# NUC121AE_v1 register map
File version: 1.0
Registers are 32-bit, read-write, reset 0x0 unless marked. A register's access mark holds for its fields unless they carry their own. Offsets are from the block's base; [hi:lo] are bit positions; {n}, {i} and the like mark numbered series.

## SCS — SYST_NVIC_SCS Register Map
Base 0xE000E000
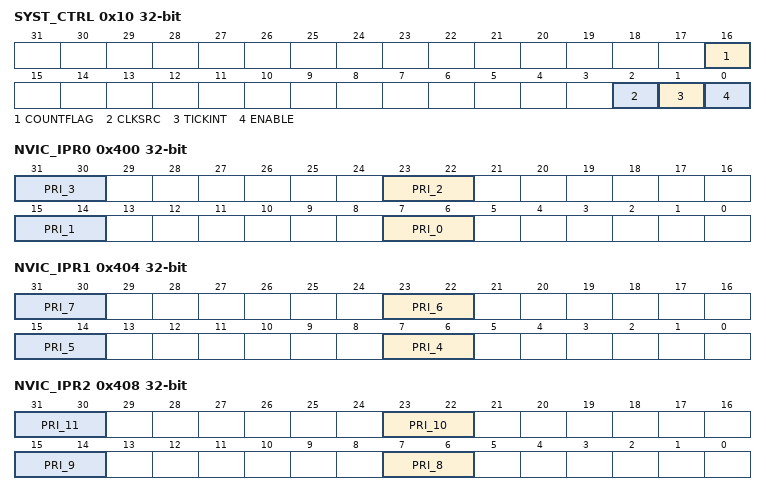
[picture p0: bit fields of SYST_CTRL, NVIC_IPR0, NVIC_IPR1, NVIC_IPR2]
0x10 SYST_CTRL — SysTick Control and Status Register
  [16] COUNTFLAG — System Tick Counter Flag. Returns 1 if timer counted to 0 since last time this register was read. COUNTFLAG is set by a count transition from 1 to 0. COUNTFLAG is cleared on read or by a write to the Current Value register.
  [2] CLKSRC — System Tick Clock Source Selection
    0=Clock source is the (optional) external reference clock; 1=Core clock used for SysTick
  [1] TICKINT — System Tick Interrupt Enabled
    0=Counting down to 0 does not cause the SysTick exception to be pended. Software can use COUNTFLAG to determine if a count to zero has occurred; 1=Counting down to 0 will cause the SysTick exception to be pended. Clearing the SysTick current value register by a register write in software will not cause SysTick to be pended
  [0] ENABLE — System Tick Counter Enabled
    0=Counter Disabled; 1=Counter will operate in a multi-shot manner
0x14 SYST_LOAD reset not defined — SysTick Reload Value Register
  [23:0] RELOAD — System Tick Reload Value. Value to load into the Current Value register when the counter reaches 0.
0x18 SYST_VAL reset not defined — SysTick Current Value Register
  [23:0] CURRENT — System Tick Current Value. Current counter value. This is the value of the counter at the time it is sampled. The counter does not provide read-modify-write protection. The register is write-clear. A software write of any value will clear the register to 0. Unsupported bits RAZ (see SysTick Reload Value register).
0x100 NVIC_ISER — IRQ0 ~ IRQ31 Set-enable Control Register
  [31:0] SETENA — Interrupt Enable Register. Enable one or more interrupts. Each bit represents an interrupt number from IRQ0 ~ IRQ31 (Vector number from 16 ~ 47). Write Operation: Read value indicates the current enable status.
    0=No effect. Associated interrupt status is Disabled; 1=Write 1 to enable associated interrupt. Associated interrupt status is Enabled
0x180 NVIC_ICER — IRQ0 ~ IRQ31 Clear-enable Control Register
  [31:0] CLRENA — Interrupt Disable Bits. Disable one or more interrupts. Each bit represents an interrupt number from IRQ0 ~ IRQ31 (Vector number from 16 ~ 47). Write Operation: Read value indicates the current enable status.
    0=No effect. Associated interrupt status is Disabled; 1=Write 1 to disable associated interrupt. Associated interrupt status is Enabled
0x200 NVIC_ISPR — IRQ0 ~ IRQ31 Set-pending Control Register
  [31:0] SETPEND — Set Interrupt Pending Register. Write Operation: Read value indicates the current pending status.
    0=No effect. Associated interrupt in not in pending status; 1=Write 1 to set pending state. Each bit represents an interrupt number from IRQ0 ~ IRQ31 (Vector number from 16 ~ 47). Associated interrupt is in pending status
0x280 NVIC_ICPR — IRQ0 ~ IRQ31 Clear-pending Control Register
  [31:0] CLRPEND — Clear Interrupt Pending Register. Write Operation: Read value indicates the current pending status.
    0=No effect. Associated interrupt in not in pending status; 1=Write 1 to clear pending state. Each bit represents an interrupt number from IRQ0 ~ IRQ31 (Vector number from 16 ~ 47). Associated interrupt is in pending status
0x400 NVIC_IPR0 — IRQ0 ~ IRQ3 Priority Control Register
  [8n+7:8n+6] PRI_{n} (n=0..3) — Priority of IRQ{n} "0" denotes the highest priority and "3" denotes the lowest priority.
0x404 NVIC_IPR1 — IRQ4 ~ IRQ7 Priority Control Register
  [8n-25:8n-26] PRI_{n} (n=4..7) — Priority of IRQ{n} "0" denotes the highest priority and "3" denotes the lowest priority.
0x408 NVIC_IPR2 — IRQ8 ~ IRQ11 Priority Control Register
  [8n-57:8n-58] PRI_{n} (n=8..11) — Priority of IRQ{n} "0" denotes the highest priority and "3" denotes the lowest priority.
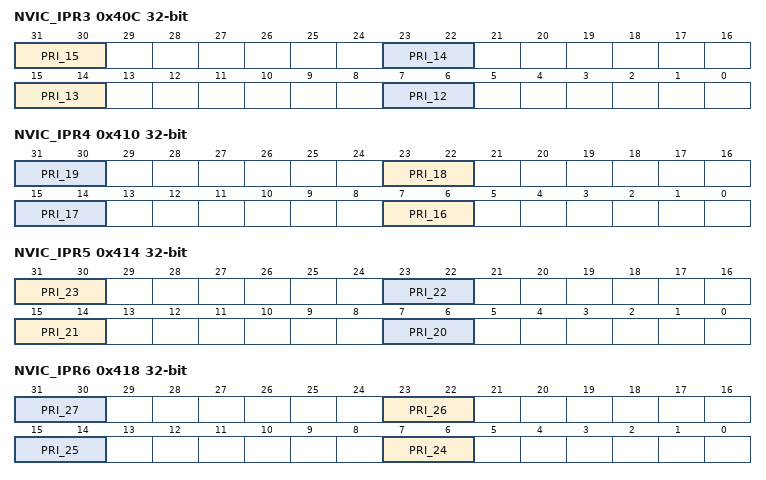
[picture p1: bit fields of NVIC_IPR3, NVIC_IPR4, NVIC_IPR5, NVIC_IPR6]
0x40C NVIC_IPR3 — IRQ12 ~ IRQ15 Priority Control Register
  [31:30] PRI_15 — Priority of IRQ15 "0" denotes the highest priority and "3" denotes the lowest priority.
  [23:22] PRI_14 — Priority of IRQ14 "0" denotes the highest priority and "3" denotes the lowest priority.
  [15:14] PRI_13 — Priority of IRQ13 "0" denotes the highest priority and "3" denotes the lowest priority
  [7:6] PRI_12 — Priority of IRQ12 "0" denotes the highest priority and "3" denotes the lowest priority.
0x410 NVIC_IPR4 — IRQ16 ~ IRQ19 Priority Control Register
  [8n-121:8n-122] PRI_{n} (n=16..19) — Priority of IRQ{n} "0" denotes the highest priority and "3" denotes the lowest priority.
0x414 NVIC_IPR5 — IRQ20 ~ IRQ23 Priority Control Register
  [31:30] PRI_23 — Priority of IRQ23 "0" denotes the highest priority and "3" denotes the lowest priority.
  [23:22] PRI_22 — Priority of IRQ22 "0" denotes the highest priority and "3" denotes the lowest priority.
  [15:14] PRI_21 — Priority of IRQ21 "0" denotes the highest priority and "3" denotes the lowest priority
  [7:6] PRI_20 — Priority of IRQ20 "0" denotes the highest priority and "3" denotes the lowest priority.
0x418 NVIC_IPR6 — IRQ24 ~ IRQ27 Priority Control Register
  [8n-185:8n-186] PRI_{n} (n=24..27) — Priority of IRQ{n} "0" denotes the highest priority and "3" denotes the lowest priority.
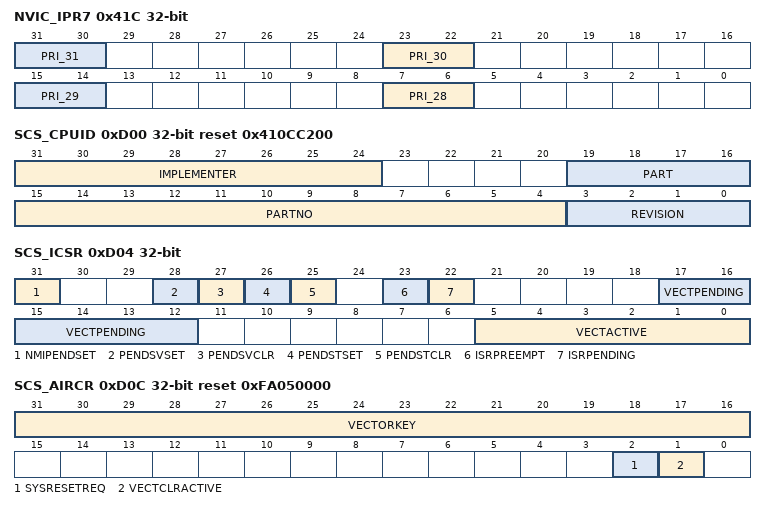
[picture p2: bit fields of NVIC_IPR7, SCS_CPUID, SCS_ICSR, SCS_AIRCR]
0x41C NVIC_IPR7 — IRQ28 ~ IRQ31 Priority Control Register
  [8n-217:8n-218] PRI_{n} (n=28..31) — Priority of IRQ{n} "0" denotes the highest priority and "3" denotes the lowest priority.
0xD00 SCS_CPUID ro reset 0x410CC200 — CPUID Register
  [31:24] IMPLEMENTER — Implementer Code Assigned by ARM
  [19:16] PART — Architecture of the Processor. Read as 0xC for ARMv6-M parts
  [15:4] PARTNO — Part Number of the Processor. Read as 0xC20.
  [3:0] REVISION — Revision Number. Read as 0x0
0xD04 SCS_ICSR — Interrupt Control and State Register
  [31] NMIPENDSET — NMI Set-pending Bit. Write Operation: Because NMI is the highest-priority exception, normally the processor enters the NMI exception handler as soon as it detects a write of 1 to this bit. Entering the handler then clears this bit to 0. This means a read of this bit by the NMI exception handler returns 1 only if the NMI signal is reasserted while the processor is executing that handler.
    0=No effect. NMI exception not pending; 1=Changes NMI exception state to pending. NMI exception pending
  [28] PENDSVSET — PendSV Set-pending Bit. Write Operation: Note: Writing 1 to this bit is the only way to set the PendSV exception state to pending.
    0=No effect. PendSV exception is not pending; 1=Changes PendSV exception state to pending. PendSV exception is pending
  [27] PENDSVCLR — PendSV Clear-pending Bit. Write Operation: This is a write only bit. When you want to clear PENDSV bit, you must "write 0 to PENDSVSET and write 1 to PENDSVCLR" at the same time.
    0=No effect; 1=Removes the pending state from the PendSV exception
  [26] PENDSTSET — SysTick Exception Set-pending Bit. Write Operation:
    0=No effect. SysTick exception is not pending; 1=Changes SysTick exception state to pending. SysTick exception is pending
  [25] PENDSTCLR — SysTick Exception Clear-pending Bit. Write Operation: This is a write only bit. When you want to clear PENDST bit, you must "write 0 to PENDSTSET and write 1 to PENDSTCLR" at the same time.
    0=No effect; 1=Removes the pending state from the SysTick exception
  [23] ISRPREEMPT — If Set, a Pending Exception Will Be Serviced on Exit From the Debug Halt State. This bit is read only.
  [22] ISRPENDING — Interrupt Pending Flag, Excluding NMI and Faults: This bit is read only.
    0=Interrupt not pending; 1=Interrupt pending
  [17:12] VECTPENDING — Indicates the Exception Number of the Highest Priority Pending Enabled Exception:
    0=No pending exceptions
  [5:0] VECTACTIVE — Contains the Active Exception Number
    0=Thread mode
0xD0C SCS_AIRCR reset 0xFA050000 — Application Interrupt and Reset Control Register
  [31:16] VECTORKEY — Register Access Key. Write Operation: When writing to this register, the VECTORKEY field need to be set to 0x05FA, otherwise the write operation would be ignored. The VECTORKEY filed is used to prevent accidental write to this register from resetting the system or clearing of the exception status. Read Operation: Read as 0xFA05.
  [2] SYSRESETREQ — System Reset Request. Writing this bit 1 will cause a reset signal to be asserted to the chip to indicate a reset is requested. The bit is a write only bit and self-clears as part of the reset sequence.
  [1] VECTCLRACTIVE — Exception Active Status Clear Bit. Reserved for debug use. When writing to the register, user must write 0 to this bit, otherwise behavior is unpredictable.
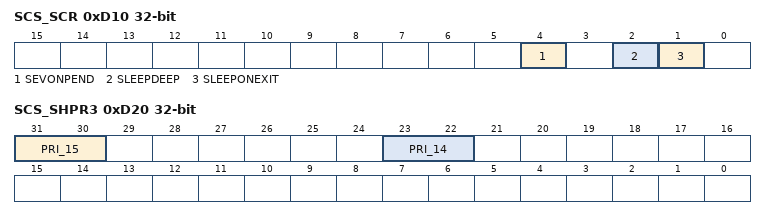
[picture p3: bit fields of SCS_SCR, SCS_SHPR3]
0xD10 SCS_SCR — System Control Register
  [4] SEVONPEND — Send Event on Pending Bit. When an event or interrupt enters pending state, the event signal wakes up the processor from WFE. If the processor is not waiting for an event, the event is registered and affects the next WFE. The processor also wakes up on execution of an SEV instruction or an external event.
    0=Only enabled interrupts or events can wake up the processor, disabled interrupts are excluded; 1=Enabled events and all interrupts, including disabled interrupts, can wake up the processor
  [2] SLEEPDEEP — Processor Deep Sleep and Sleep Mode Selection. Controls whether the processor uses sleep or deep sleep as its low power mode:
    0=Sleep mode; 1=Deep Sleep mode
  [1] SLEEPONEXIT — Sleep-on-exit Enable Bit. This bit indicates sleep-on-exit when returning from Handler mode to Thread mode. Setting this bit to 1 enables an interrupt driven application to avoid returning to an empty main application..
    0=Do not sleep when returning to Thread mode; 1=Enter Sleep or Deep Sleep when returning from ISR to Thread mode
0xD1C SCS_SHPR2 — System Handler Priority Register 2
  [31:30] PRI_11 — Priority of System Handler 11 - SVCall "0" denotes the highest priority and "3" denotes the lowest priority
0xD20 SCS_SHPR3 — System Handler Priority Register 3
  [31:30] PRI_15 — Priority of System Handler 15 - SysTick "0" denotes the highest priority and "3" denotes the lowest priority
  [23:22] PRI_14 — Priority of System Handler 14 - PendSV "0" denotes the highest priority and "3" denotes the lowest priority
